# ESP32S31_RADIO register map
Vendor: Espressif; Series: ESP32-S31; File version: 3.52
Registers are 32-bit, read-write, no defined reset value unless marked. A register's access mark holds for its fields unless they carry their own. Offsets are from the block's base; [hi:lo] are bit positions; lines under a group give offsets from that group; 'fields as' and 'values as' point back to an identical list.

## PHY_PBUS — PBus command, mode, status/clock/force and packed result windows recovered from complete rev0 ROM bodies and their address/shift jump tables. The blob debug printer independently names selector/path groups: RFRX is selector 0 paths 1/2; BB is selector 1 paths 1/2; DCO is selectors 2/3 paths 1/2; RFTX is selector 4 paths 1/2 and selector 5 path 1.
Base 0x20100880
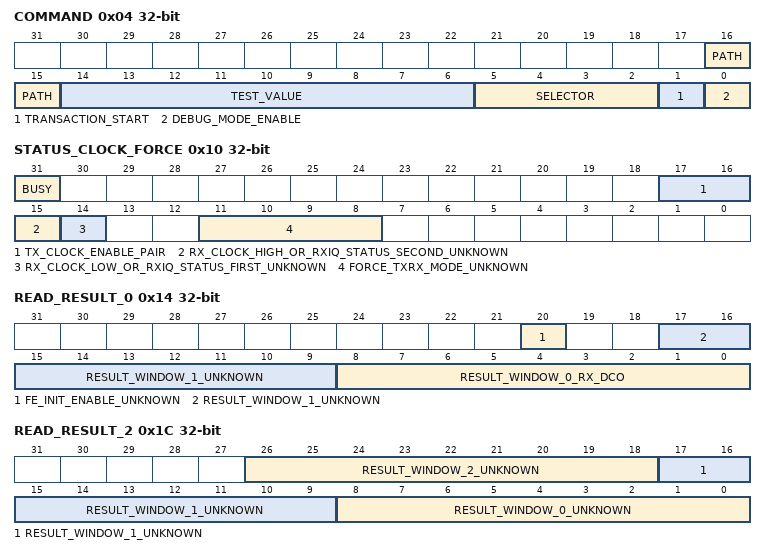
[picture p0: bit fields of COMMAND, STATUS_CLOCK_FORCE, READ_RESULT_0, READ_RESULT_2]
0x04 COMMAND — phy_pbus_force_test command word; phy_pbus_force_mode also uses bit 0 as the debug/work selector. The complete force-test body at 0x2f824228 composes selector, test value and path first, then masks the combined image with 0x0001fffc. It does not independently narrow the signed halfword values supplied by phy_pbus_rx_dco_cal at 0x2f828f44, so their retained high bits can contribute to the physical PATH field.
  [16:15] PATH — Physical two-bit path field. High retained bits of a wide test-value argument are ORed into this field by the complete ROM command encoder. The debug printer exercises paths 1 and 2 for RFRX, BB, DCO and selector-4 RFTX, and path 1 for selector-5 RFTX.
  [14:6] TEST_VALUE — Physical nine-bit value field. The ROM publication expression accepts a wider signed halfword before the combined command mask; use the PAC ROM encoder when reproducing that behavior.
  [5:2] SELECTOR — Debug group selector: 0 RFRX, 1 BB, 2/3 DCO, 4/5 RFTX for the evidenced paths. Treat other selector/path combinations as undocumented.
  [1] TRANSACTION_START
  [0] DEBUG_MODE_ENABLE
0x0C MODE — PBus debug/work mode selector used by complete phy_pbus_force_mode.
  [26] WORK_MODE_ENABLE
0x10 STATUS_CLOCK_FORCE — One physical multifunction word independently used for TX/RX forcing, RX/TX clock pairs and PBus busy status.
  [31] BUSY
  [17:16] TX_CLOCK_ENABLE_PAIR — phy_set_txclk_en writes both bits as a pair; individual clock identities are unknown.
    on write: 0=DISABLED (Disable both recovered TX clock bits.); 3=ENABLED (Enable both recovered TX clock bits.)
  [15] RX_CLOCK_HIGH_OR_RXIQ_STATUS_SECOND_UNKNOWN — phy_set_rxclk_en writes this bit with its neighbor as a pair; complete phy_rxiq_cal_init independently sets it at root entry and clears it during the successful cleanup suffix. The shared electrical identity remains unknown.
  [14] RX_CLOCK_LOW_OR_RXIQ_STATUS_FIRST_UNKNOWN — phy_set_rxclk_en writes this bit with its neighbor as a pair; complete phy_rxiq_cal_init independently sets it first at root entry. The shared electrical identity remains unknown.
  [11:8] FORCE_TXRX_MODE_UNKNOWN — phy_force_txrx_off replaces bits 11:8 with one of four evidenced encodings; the individual bit meanings remain unknown.
    on write: 8=ENABLE_INITIAL_PHASE (First force-TX/RX enable write in complete phy_force_txrx_off.); 10=ENABLE_FINAL_PHASE (Second force-TX/RX enable write in complete phy_force_txrx_off.); 2=DISABLE_INITIAL_PHASE (First force-TX/RX disable write in complete phy_force_txrx_off.); 0=DISABLE_FINAL_PHASE (Second force-TX/RX disable write in complete phy_force_txrx_off.)
0x14 READ_RESULT_0 — Shared PBus/FE word. Selector 1 reads result window 0 for non-path-1 operations, including RX-DCO, and window 1 for path 1. Complete phy_fe_reg_init independently sets bit 20 through a fresh-read RMW.
  [20] FE_INIT_ENABLE_UNKNOWN — First complete phy_fe_reg_init RMW sets bit 20.
  [17:9] RESULT_WINDOW_1_UNKNOWN ro
  [8:0] RESULT_WINDOW_0_RX_DCO ro
0x18 READ_RESULT_1 ro — Selector 2 path 1 reads window 0; other bits are not presently evidenced.
  [8:0] RESULT_WINDOW_0_UNKNOWN
0x1C READ_RESULT_2 ro — Selector 3 reads windows 0/1; selector 2 non-path-1 reads window 2.
  [26:18] RESULT_WINDOW_2_UNKNOWN, [17:9] RESULT_WINDOW_1_UNKNOWN, [8:0] RESULT_WINDOW_0_UNKNOWN
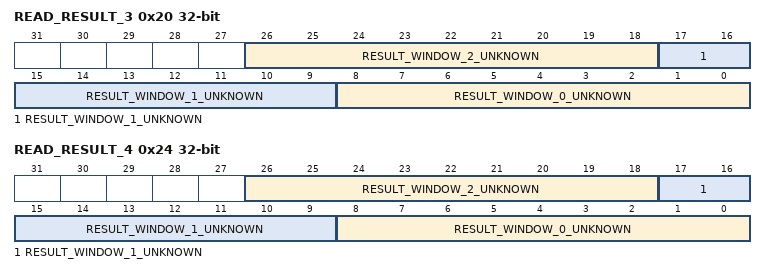
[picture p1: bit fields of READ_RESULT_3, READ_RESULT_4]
0x20 READ_RESULT_3 ro — Selector 4 path 1 reads window 0; selector 0 non-path-one reads window 1 and path one reads window 2.
  fields as READ_RESULT_2
0x24 READ_RESULT_4 ro — Selectors above five fall back to window 0, selector 5 reads window 1, and selector 4 non-path-one reads window 2.
  fields as READ_RESULT_2
